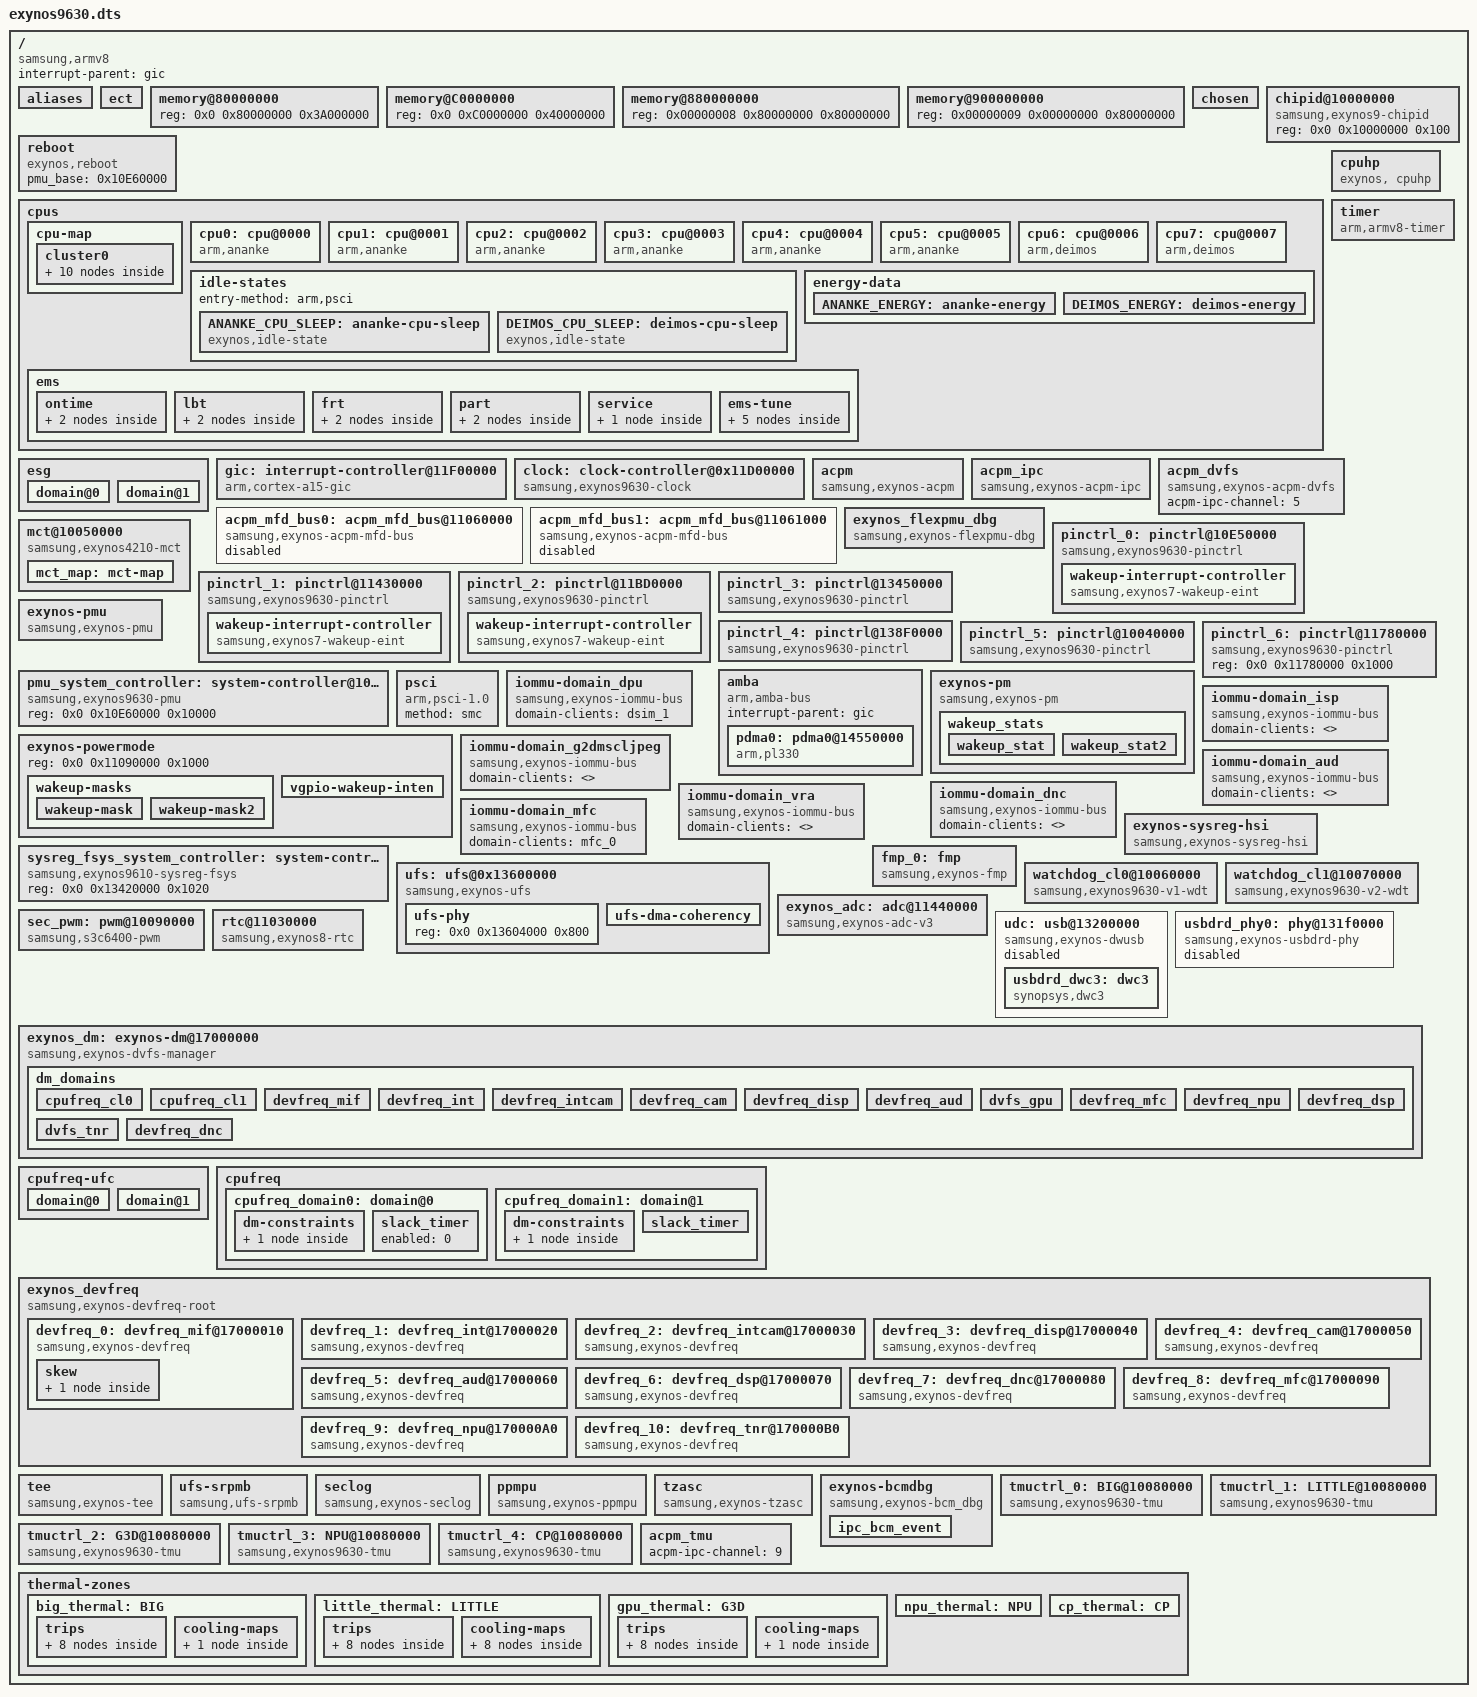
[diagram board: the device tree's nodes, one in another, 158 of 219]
/*
 * SAMSUNG EXYNOS9630 SoC device tree source
 *
 * Copyright (c) 2019 Samsung Electronics Co., Ltd.
 *		http://www.samsung.com
 *
 * SAMSUNG EXYNOS9630 SoC device nodes are listed in this file.
 * EXYNOS9630 based board files can include this file and provide
 * values for board specfic bindings.
 *
 * This program is free software; you can redistribute it and/or modify
 * it under the terms of the GNU General Public License version 2 as
 * published by the Free Software Foundation.
 */

/dts-v1/;
#include <dt-bindings/interrupt-controller/arm-gic.h>
#include <dt-bindings/interrupt-controller/exynos9630.h>
#include <dt-bindings/soc/samsung/exynos-bcm_dbg.h>
#include <dt-bindings/clock/exynos9630.h>
#include "exynos9630-pinctrl.dtsi"
#include "exynos9630-usi.dtsi"
#include "exynos9630-rmem.dtsi"
#include "exynos9630-bts.dtsi"
#include "exynos9630-dpu.dtsi"
#include "exynos9630-sysmmu.dtsi"
#include <dt-bindings/ufs/ufs.h>
#include "exynos9630-mali.dtsi"
#include <dt-bindings/soc/samsung/exynos9630-dm.h>
#include <dt-bindings/soc/samsung/exynos9630-devfreq.h>
#include "exynos9630-pm-domains.dtsi"
#include "exynos9630-debug.dtsi"
#include <dt-bindings/thermal/thermal.h>
#include "exynos9630-mfc.dtsi"

/ {
	compatible = "samsung,armv8", "samsung,exynos9630";
	interrupt-parent = <&gic>;
	#address-cells = <2>;
	#size-cells = <1>;

	aliases {
		pinctrl0 = &pinctrl_0;
		pinctrl1 = &pinctrl_1;
		pinctrl2 = &pinctrl_2;
		pinctrl3 = &pinctrl_3;
		pinctrl4 = &pinctrl_4;
		pinctrl5 = &pinctrl_5;
		pinctrl6 = &pinctrl_6;
		uart0 = &serial_0;
		fmp0 = &fmp_0;
		mfc0 = &mfc_0;
	};

	ect {
		parameter_address = <0x90000000>;
		parameter_size = <0x4B000>;
	};

	memory@80000000 {
		device_type = "memory";
		reg = <0x0 0x80000000 0x3A000000>;
	};

	memory@C0000000 {
		device_type = "memory";
		reg = <0x0 0xC0000000 0x40000000>;
	};

	memory@880000000 {
		device_type = "memory";
		reg = <0x00000008 0x80000000 0x80000000>;
	};

	memory@900000000 {
		device_type = "memory";
		reg = <0x00000009 0x00000000 0x80000000>;
	};

	chosen: chosen {
		bootargs = "console=ram skip_initramfs rootwait ro init=/init root=/dev/sda12 clk_ignore_unused androidboot.hardware=exynos9630 androidboot.selinux=enforce androidboot.debug_level=0x4948 firmware_class.path=/vendor/firmware sec_debug.cp=0";
		linux,initrd-start = <0x84000000>;
		linux,initrd-end = <0x841FFFFF>;
	};

	chipid@10000000 {
		compatible = "samsung,exynos9-chipid";
		reg = <0x0 0x10000000 0x100>;
	};

	reboot {
		compatible = "exynos,reboot";
		pmu_base = <0x10E60000>;
	};

	cpus {
		#address-cells = <2>;
		#size-cells = <0>;

		cpu-map {
			cluster0 {
				coregroup0 {
					core0 {
						cpu = <&cpu0>;
					};
					core1 {
						cpu = <&cpu1>;
					};
					core2 {
						cpu = <&cpu2>;
					};
					core3 {
						cpu = <&cpu3>;
					};
					core4 {
						cpu = <&cpu4>;
					};
					core5 {
						cpu = <&cpu5>;
					};
				};
				coregroup1 {
					core0 {
						cpu = <&cpu6>;
					};
					core1 {
						cpu = <&cpu7>;
					};
				};
			};
		};

		cpu0: cpu@0000 {
			device_type = "cpu";
			compatible = "arm,ananke", "arm,armv8";
			reg = <0x0 0x0>;
			enable-method = "psci";
			sched-energy-data = <&ANANKE_ENERGY>;
			cpu-idle-states = <&ANANKE_CPU_SLEEP>;
		};
		cpu1: cpu@0001 {
			device_type = "cpu";
			compatible = "arm,ananke", "arm,armv8";
			reg = <0x0 0x0001>;
			enable-method = "psci";
			sched-energy-data = <&ANANKE_ENERGY>;
			cpu-idle-states = <&ANANKE_CPU_SLEEP>;
		};
		cpu2: cpu@0002 {
			device_type = "cpu";
			compatible = "arm,ananke", "arm,armv8";
			reg = <0x0 0x0002>;
			enable-method = "psci";
			sched-energy-data = <&ANANKE_ENERGY>;
			cpu-idle-states = <&ANANKE_CPU_SLEEP>;
		};
		cpu3: cpu@0003 {
			device_type = "cpu";
			compatible = "arm,ananke", "arm,armv8";
			reg = <0x0 0x0003>;
			enable-method = "psci";
			sched-energy-data = <&ANANKE_ENERGY>;
			cpu-idle-states = <&ANANKE_CPU_SLEEP>;
		};
		cpu4: cpu@0004 {
			device_type = "cpu";
			compatible = "arm,ananke", "arm,armv8";
			reg = <0x0 0x0004>;
			enable-method = "psci";
			sched-energy-data = <&ANANKE_ENERGY>;
			cpu-idle-states = <&ANANKE_CPU_SLEEP>;
		};
		cpu5: cpu@0005 {
			device_type = "cpu";
			compatible = "arm,ananke", "arm,armv8";
			reg = <0x0 0x0005>;
			enable-method = "psci";
			sched-energy-data = <&ANANKE_ENERGY>;
			cpu-idle-states = <&ANANKE_CPU_SLEEP>;
		};
		cpu6: cpu@0006 {
			device_type = "cpu";
			compatible = "arm,deimos", "arm,armv8";
			reg = <0x0 0x0006>;
			enable-method = "psci";
			sched-energy-data = <&DEIMOS_ENERGY>;
			cpu-idle-states = <&DEIMOS_CPU_SLEEP>;
		};
		cpu7: cpu@0007 {
			device_type = "cpu";
			compatible = "arm,deimos", "arm,armv8";
			reg = <0x0 0x0007>;
			enable-method = "psci";
			sched-energy-data = <&DEIMOS_ENERGY>;
			cpu-idle-states = <&DEIMOS_CPU_SLEEP>;
		};
		
		idle-states {
			entry-method = "arm,psci";

			ANANKE_CPU_SLEEP: ananke-cpu-sleep {
				idle-state-name = "c2";
				compatible = "exynos,idle-state";
				arm,psci-suspend-param = <0x0010000>;
				entry-latency-us = <70>;
				exit-latency-us = <160>;
				min-residency-us = <2000>;
				status = "okay";
			};

			DEIMOS_CPU_SLEEP: deimos-cpu-sleep {
				idle-state-name = "c2";
				compatible = "exynos,idle-state";
				arm,psci-suspend-param = <0x0010000>;
				entry-latency-us = <150>;
				exit-latency-us = <190>;
				min-residency-us = <2500>;
				status = "okay";
			};
		};

		energy-data {
			ANANKE_ENERGY: ananke-energy {
				capacity-mips = <272>;
				power-coefficient = <160>;
				capacity-mips-s = <215>;
				power-coefficient-s = <130>;
				static-power-coefficient = <45>;

				capacity-weight = <1>;
				energy-weight = <1>;
				capacity-weight-perf = <2>;
				energy-weight-perf = <1>;
			};
			DEIMOS_ENERGY: deimos-energy {
				capacity-mips = <785>;
				power-coefficient = <760>;
				capacity-mips-s = <365>;
				power-coefficient-s = <506>;
				static-power-coefficient = <289>;

				capacity-weight = <1>;
				energy-weight = <3>;
				capacity-weight-perf = <3>;
				energy-weight-perf = <1>;
			};
		};

		ems {
			/* Ontime Migration */
			ontime {
				/* little cores */
				coregroup0 {
					lower-boundary = <0>;
					upper-boundary = <106>;
					lower-boundary-s = <0>;
					upper-boundary-s = <60>;
				};
				/* big cores */
				coregroup1 {
					lower-boundary = <204>;
					upper-boundary = <0xffffffff>;
					lower-boundary-s = <309>;
					upper-boundary-s = <0xffffffff>;
				};
			};

			/* Load Balance Trigger */
			#define DEFAULT_RATIO	80
			lbt {
				overutil-level0 {
					cpus =	"0-5",
						"6-7";
					ratio =	<25>,
						<30>;
				};
				overutil-level1 {
					cpus = "0-7";
					ratio = <DEFAULT_RATIO>;
				};
			};

			/* FRT Migration */
			frt {
				/* little cores */
				coregroup0 {
					coverage-ratio = <30>;
					active-ratio = <25>;
				};
				/* big cores */
				coregroup1 {
					coverage-ratio = <30>;
					active-ratio = <5>;
				};
			};

			part {
				/* little cores */
				coregroup0 {
					active-ratio-limit = <43>;
					active-ratio-boost = <42>;
				};
				/* big cores */
				coregroup1 {
					active-ratio-limit = <30>;
					active-ratio-boost = <0>;
				};
			};

			service {
				prefer-perf0 {
					boost = <1>;
					prefer-cpus =	"6-7",
						"0-5";
					light-task-threshold = <10>;
					light-task-threshold-s = <6>;
					light-prefer-cpus = "0-5";
				};
			};

			ems-tune {
				root {
					boost_ratio = <0 0 0>;
				};
				foreground {
					boost_ratio = <0 0 0>;
				};
				background {
					boost_ratio = <0 0 0>;
				};
				top-app {
					boost_ratio = <5 5 5>;
				};
				rt {
					boost_ratio = <0 0 0>;
				};
			};
		};

	};

	esg {
		domain@0 {
			device_type = "esgov-pol0";
			shared-cpus = "0-5";
			pm_qos-min-class = <3>;
			pm_qos-max-class = <4>;
			step = <4>;
		};
		domain@1 {
			device_type = "esgov-pol6";
			shared-cpus = "6-7";
			pm_qos-min-class = <5>;
			pm_qos-max-class = <6>;
			step = <8>;
		};
	};

	cpuhp {
		compatible = "exynos, cpuhp";
	};


	gic:interrupt-controller@11F00000 {
		compatible = "arm,cortex-a15-gic", "arm,cortex-a9-gic";
		#interrupt-cells = <3>;
		#address-cells = <0>;
		interrupt-controller;
		reg =	<0x0 0x11F01000 0x1000>,
			<0x0 0x11F02000 0x1000>,
			<0x0 0x11F04000 0x2000>,
			<0x0 0x11F06000 0x2000>;
		interrupts = <GIC_PPI 9 (GIC_CPU_MASK_SIMPLE(4) | IRQ_TYPE_LEVEL_HIGH)>;
	};

	timer {
		compatible = "arm,armv8-timer";
		interrupts = <GIC_PPI 13
				(GIC_CPU_MASK_SIMPLE(8) | IRQ_TYPE_LEVEL_LOW)>,
			     <GIC_PPI 14
				(GIC_CPU_MASK_SIMPLE(8) | IRQ_TYPE_LEVEL_LOW)>,
			     <GIC_PPI 11
				(GIC_CPU_MASK_SIMPLE(8) | IRQ_TYPE_LEVEL_LOW)>,
			     <GIC_PPI 10
				(GIC_CPU_MASK_SIMPLE(8) | IRQ_TYPE_LEVEL_LOW)>;
	        clock-frequency = <26000000>;
		use-clocksource-only;
		use-physical-timer;
	};

	clock: clock-controller@0x11D00000 {
		compatible = "samsung,exynos9630-clock";
		reg = <0x0 0x11D00000 0x8000>;
		#clock-cells = <1>;
		acpm-ipc-channel = <0>;
	};

	acpm {
		compatible = "samsung,exynos-acpm";
		#address-cells = <2>;
		#size-cells = <1>;
		acpm-ipc-channel = <4>;
		fvmap_offset = <0xCC00>;
		reg = <0x0 0x10E30000 0x1000>;		/* TIMER_APM */
		reg-names = "timer_apm";
		peritimer-cnt = <0xFFFF>;
	};

	acpm_ipc {
		compatible = "samsung,exynos-acpm-ipc";
		#address-cells = <2>;
		#size-cells = <1>;
		interrupts = <GIC_SPI INTREQ__MAILBOX_APM2AP IRQ_TYPE_LEVEL_HIGH>;	/* AP2APM MAILBOX SPI NUM*/
		reg = <0x0 0x10F00000 0x1000>,		/* AP2APM MAILBOX */
			<0x0 0x2039000 0x30000>;	/* APM SRAM */
		initdata-base = <0x7000>;
		num-timestamps = <32>;
		debug-log-level = <0>;
		logging-period = <500>;
		dump-base = <0x203C000>;
		dump-size = <0x2D000>;			/* 180KB */
	};

	acpm_dvfs {
		compatible = "samsung,exynos-acpm-dvfs";
		acpm-ipc-channel = <5>;
	};

	acpm_mfd_bus0: acpm_mfd_bus@11060000 {
		compatible = "samsung,exynos-acpm-mfd-bus";
		status = "disabled";
	};

	acpm_mfd_bus1: acpm_mfd_bus@11061000 {
		compatible = "samsung,exynos-acpm-mfd-bus";
		status = "disabled";
	};

	exynos_flexpmu_dbg {
		compatible = "samsung,exynos-flexpmu-dbg";
		#address-cells = <2>;
		#size-cells = <1>;
		data-base = <0x204f800>;
		data-size = <0x400>;
	};

	mct@10050000 {
		compatible = "samsung,exynos4210-mct";
		reg = <0x0 0x10050000 0x800>;
		interrupt-controller;
		#interrupt-cells = <1>;
		interrupt-parent = <&mct_map>;
		interrupts =	<0>, <1>, <2>, <3>,
				<4>, <5>, <6>, <7>,
				<8>, <9>, <10>, <11>;
		clocks = <&clock OSCCLK>, <&clock GATE_MCT_QCH>;
		clock-names = "fin_pll", "mct";
		use-clockevent-only;

		mct_map: mct-map {
			#interrupt-cells = <1>;
			#address-cells = <0>;
			#size-cells = <0>;
			interrupt-map = <0 &gic 0 INTREQ__MCT_G0 IRQ_TYPE_LEVEL_HIGH>,
					<1 &gic 0 INTREQ__MCT_G1 IRQ_TYPE_LEVEL_HIGH>,
					<2 &gic 0 INTREQ__MCT_G2 IRQ_TYPE_LEVEL_HIGH>,
					<3 &gic 0 INTREQ__MCT_G3 IRQ_TYPE_LEVEL_HIGH>,
					<4 &gic 0 INTREQ__MCT_L0 IRQ_TYPE_LEVEL_HIGH>,
					<5 &gic 0 INTREQ__MCT_L1 IRQ_TYPE_LEVEL_HIGH>,
					<6 &gic 0 INTREQ__MCT_L2 IRQ_TYPE_LEVEL_HIGH>,
					<7 &gic 0 INTREQ__MCT_L3 IRQ_TYPE_LEVEL_HIGH>,
					<8 &gic 0 INTREQ__MCT_L4 IRQ_TYPE_LEVEL_HIGH>,
					<9 &gic 0 INTREQ__MCT_L5 IRQ_TYPE_LEVEL_HIGH>,
					<10 &gic 0 INTREQ__MCT_L6 IRQ_TYPE_LEVEL_HIGH>,
					<11 &gic 0 INTREQ__MCT_L7 IRQ_TYPE_LEVEL_HIGH>;
		};
	};

	/* ALIVE */
	pinctrl_0: pinctrl@10E50000 {
		compatible = "samsung,exynos9630-pinctrl";
		reg = <0x0 0x10E50000 0x1000>;
		interrupts = <GIC_SPI INTREQ__ALIVE_EINT0 0>,
			     <GIC_SPI INTREQ__ALIVE_EINT1 0>,
			     <GIC_SPI INTREQ__ALIVE_EINT2 0>,
			     <GIC_SPI INTREQ__ALIVE_EINT3 0>,
			     <GIC_SPI INTREQ__ALIVE_EINT4 0>,
			     <GIC_SPI INTREQ__ALIVE_EINT5 0>,
			     <GIC_SPI INTREQ__ALIVE_EINT6 0>,
			     <GIC_SPI INTREQ__ALIVE_EINT7 0>,
			     <GIC_SPI INTREQ__ALIVE_EINT8 0>,
			     <GIC_SPI INTREQ__ALIVE_EINT9 0>,
			     <GIC_SPI INTREQ__ALIVE_EINT10 0>,
			     <GIC_SPI INTREQ__ALIVE_EINT11 0>;

		wakeup-interrupt-controller {
			compatible = "samsung,exynos7-wakeup-eint";
		};
	};

	/* CMGP */
	pinctrl_1: pinctrl@11430000 {
		compatible = "samsung,exynos9630-pinctrl";
		reg = <0x0 0x11430000 0x1000>;
		interrupts = <GIC_SPI INTREQ__EXT_INTM00 IRQ_TYPE_LEVEL_HIGH>,
			     <GIC_SPI INTREQ__EXT_INTM01 IRQ_TYPE_LEVEL_HIGH>,
			     <GIC_SPI INTREQ__EXT_INTM02 IRQ_TYPE_LEVEL_HIGH>,
			     <GIC_SPI INTREQ__EXT_INTM03 IRQ_TYPE_LEVEL_HIGH>,
			     <GIC_SPI INTREQ__EXT_INTM04 IRQ_TYPE_LEVEL_HIGH>,
			     <GIC_SPI INTREQ__EXT_INTM05 IRQ_TYPE_LEVEL_HIGH>,
			     <GIC_SPI INTREQ__EXT_INTM06 IRQ_TYPE_LEVEL_HIGH>,
			     <GIC_SPI INTREQ__EXT_INTM07 IRQ_TYPE_LEVEL_HIGH>,
			     <GIC_SPI INTREQ__EXT_INTM08 IRQ_TYPE_LEVEL_HIGH>,
			     <GIC_SPI INTREQ__EXT_INTM09 IRQ_TYPE_LEVEL_HIGH>,
			     <GIC_SPI INTREQ__EXT_INTM10 IRQ_TYPE_LEVEL_HIGH>,
			     <GIC_SPI INTREQ__EXT_INTM11 IRQ_TYPE_LEVEL_HIGH>,
			     <GIC_SPI INTREQ__EXT_INTM12 IRQ_TYPE_LEVEL_HIGH>,
			     <GIC_SPI INTREQ__EXT_INTM13 IRQ_TYPE_LEVEL_HIGH>,
			     <GIC_SPI INTREQ__EXT_INTM14 IRQ_TYPE_LEVEL_HIGH>,
			     <GIC_SPI INTREQ__EXT_INTM15 IRQ_TYPE_LEVEL_HIGH>;

		wakeup-interrupt-controller {
			compatible = "samsung,exynos7-wakeup-eint";
		};
	};

	/* CHUB */
	pinctrl_2: pinctrl@11BD0000 {
		compatible = "samsung,exynos9630-pinctrl";
		reg = <0x0 0x11BD0000 0x1000>;
		interrupts = <GIC_SPI INTREQ__EXT_INTH0_0 IRQ_TYPE_LEVEL_HIGH>,
			     <GIC_SPI INTREQ__EXT_INTH0_1 IRQ_TYPE_LEVEL_HIGH>,
			     <GIC_SPI INTREQ__EXT_INTH0_2 IRQ_TYPE_LEVEL_HIGH>,
			     <GIC_SPI INTREQ__EXT_INTH0_3 IRQ_TYPE_LEVEL_HIGH>,
			     <GIC_SPI INTREQ__EXT_INTH0_4 IRQ_TYPE_LEVEL_HIGH>,
			     <GIC_SPI INTREQ__EXT_INTH0_5 IRQ_TYPE_LEVEL_HIGH>,
			     <GIC_SPI INTREQ__EXT_INTH0_6 IRQ_TYPE_LEVEL_HIGH>,
			     <GIC_SPI INTREQ__EXT_INTH0_7 IRQ_TYPE_LEVEL_HIGH>,
			     <GIC_SPI INTREQ__EXT_INTH1_0 IRQ_TYPE_LEVEL_HIGH>,
			     <GIC_SPI INTREQ__EXT_INTH1_1 IRQ_TYPE_LEVEL_HIGH>,
			     <GIC_SPI INTREQ__EXT_INTH1_2 IRQ_TYPE_LEVEL_HIGH>,
			     <GIC_SPI INTREQ__EXT_INTH1_3 IRQ_TYPE_LEVEL_HIGH>,
			     <GIC_SPI INTREQ__EXT_INTH2_0 IRQ_TYPE_LEVEL_HIGH>,
			     <GIC_SPI INTREQ__EXT_INTH2_1 IRQ_TYPE_LEVEL_HIGH>,
			     <GIC_SPI INTREQ__EXT_INTH2_2 IRQ_TYPE_LEVEL_HIGH>,
			     <GIC_SPI INTREQ__EXT_INTH2_3 IRQ_TYPE_LEVEL_HIGH>,
			     <GIC_SPI INTREQ__EXT_INTH2_4 IRQ_TYPE_LEVEL_HIGH>,
			     <GIC_SPI INTREQ__EXT_INTH2_5 IRQ_TYPE_LEVEL_HIGH>;

		wakeup-interrupt-controller {
			compatible = "samsung,exynos7-wakeup-eint";
		};
	};

	/* HSI */
	pinctrl_3: pinctrl@13450000 {
		compatible = "samsung,exynos9630-pinctrl";
		reg = <0x0 0x13450000 0x1000>;
		interrupts = <GIC_SPI INTREQ__GPIO_HSI 0>;
	};

	/* MMCCARD */
	pinctrl_4: pinctrl@138F0000{
		compatible = "samsung,exynos9630-pinctrl";
		reg = <0x0 0x138F0000 0x1000>;
		interrupts = <GIC_SPI INTREQ__GPIO_MMCCARD 0>;
	};

	/* PERI */
	pinctrl_5: pinctrl@10040000 {
		compatible = "samsung,exynos9630-pinctrl";
		reg = <0x0 0x10040000 0x1000>;
		interrupts = <GIC_SPI INTREQ__GPIO_PERI 0>;
	};

	/* VTS */
	pinctrl_6: pinctrl@11780000 {
		compatible = "samsung,exynos9630-pinctrl";
		reg = <0x0 0x11780000 0x1000>;
	};

	exynos-pmu {
		compatible = "samsung,exynos-pmu";
		samsung,syscon-phandle = <&pmu_system_controller>;
		reg = <0x0 0x10E60000 0x10000>;
		reg-names = "pmu_alive";
	};

	pmu_system_controller: system-controller@10E60000 {
		compatible = "samsung,exynos9630-pmu", "syscon";
		reg = <0x0 0x10E60000 0x10000>;
	};

	/* DMA */
	amba {
		#address-cells = <2>;
		#size-cells = <1>;
		compatible = "arm,amba-bus";
		interrupt-parent = <&gic>;
		ranges;

		pdma0: pdma0@14550000 {
			compatible = "arm,pl330", "arm,primecell";
			reg = <0x0 0x14550000 0x1000>;
			interrupts = <0 37 0>;
			clocks = <&clock GATE_PDMA_BUSC_QCH>;
			clock-names = "apb_pclk";
			#dma-cells = <1>;
			#dma-channels = <8>;
			#dma-requests = <32>;
			#dma-multi-irq = <1>;
			dma-arwrapper = <0x14554400>,
					<0x14554420>,
					<0x14554440>,
					<0x14554460>,
					<0x14554480>,
					<0x145544A0>,
					<0x145544C0>,
					<0x145544E0>;
			dma-awwrapper = <0x14554404>,
					<0x14554424>,
					<0x14554444>,
					<0x14554464>,
					<0x14554484>,
					<0x145544A4>,
					<0x145544C4>,
					<0x145544E4>;
			dma-instwrapper = <0x14554500>;
			dma-mask-bit = <36>;
			coherent-mask-bit = <36>;
		};
	};

	psci {
		compatible = "arm,psci-1.0";
		method = "smc";
	};

	exynos-pm {
		compatible = "samsung,exynos-pm";
		reg = <0x0 0x10E50000 0x1000>,
		    <0x0 0x11F01200 0x100>;
		reg-names = "gpio_alive_base",
			"gicd_ispendrn_base";
		num-eint = <12>;
		num-gic = <16>;
		suspend_mode_idx = <8>;         /* SYS_SLEEP */
		suspend_psci_idx = <1024>;      /* PSCI_SYSTEM_SLEEP */

		usbl2_suspend_available = <0>;  /* SYS_SLEEP_USBL2 */
		usbl2_suspend_mode_idx = <12>;  /* PSCI_SYSTEM_SLEEP */

		/* WAKEUP_STAT,      WAKEUP2_STAT*/
		wakeup_stat = <0x3950>,         <0x3954>;

		wake_lock = <0>;		/* 1: held wake_lock */

		wakeup_stats {
			wakeup_stat {
				ws-name =
					"RTC_ALARM",		/* [ 0] */
					"RTC_TICK",		/* [ 1] */
					"TRTC_ALARM",		/* [ 2] */
					"TRTC_TICK",		/* [ 3] */
					"SPARE",		/* [ 4] */
					"CMGP2PMU_AP_EINT0",	/* [ 5] */
					"CMGP2PMU_AP_EINT1",	/* [ 6] */
					"MAILBOX_APM2AP",	/* [ 7] */
					"MAILBOX_CP2AP",	/* [ 8] */
					"MAILBOX_VTS2AP",	/* [ 9] */
					"S_MAILBOX_CP2AP",	/* [10] */
					"VTS_WDT",		/* [11] */
					"EINT",			/* [12] */
					"MAILBOX_GNSS2AP",	/* [13] */
					"MAILBOX_WLBT2AP",	/* [14] */
					"MAILBOX_CHUB2AP",	/* [15] */
					"RESETREQ_CP",		/* [16] */
					"RESETREQ_GNSS",	/* [17] */
					"RESETREQ_WLBT",	/* [18] */
					"USB_REWA",		/* [19] */
					"USBDP",		/* [20] */
					"MMC_CARD",		/* [21] */
					"TIMER",		/* [22] */
					"CLUSTER0_CPU0_nIRQ",	/* [23] */
					"CLUSTER0_CPU1_nIRQ",	/* [24] */
					"CLUSTER0_CPU2_nIRQ",	/* [25] */
					"CLUSTER0_CPU3_nIRQ",	/* [26] */
					"CLUSTER0_CPU4_nIRQ",	/* [27] */
					"CLUSTER0_CPU5_nIRQ",	/* [28] */
					"CLUSTER1_CPU0_nIRQ",	/* [29] */
					"CLUSTER1_CPU1_nIRQ",	/* [30] */
					"CHUB_WDT";		/* [31] */
			};
			wakeup_stat2 {
				ws-name =
					"CP_ACTIVE",		/* [ 0] */
					"GNSS_ACTIVE",		/* [ 1] */
					"WLBT_ACTIVE",		/* [ 2] */
					"USB20_VMINUS",		/* [ 3] */
					"USB20_VPLUS",		/* [ 4] */
					"RESERVED",		/* [ 5] */
					"RESERVED",		/* [ 6] */
					"RESERVED",		/* [ 7] */
					"MMC_EMBD",		/* [ 8] */
					"GNSS2AP_WAKUP_INT_REQ",/* [ 9] */
					"CHUB2PMU_AP_EINT0",	/* [10] */
					"CHUB2PMU_AP_EINT1",	/* [11] */
					"VGPIO2PMU_EINT0",	/* [12] */
					"VGPIO2PMU_EINT1";	/* [13] */
			};
		};
	};

	exynos-powermode {
		reg = <0x0 0x11090000 0x1000>;
		reg-names = "sysreg_vgpio2pmu";

		wakeup-masks {
			/*
			 * wakeup_mask configuration
			 *	        SICD		SICD_CPD	AFTR		STOP
			 *              LPD		LPA		ALPA		DSTOP
			 *              SLEEP		SLEEP_VTS_ON	SLEEP_AUD_ON	FAPO
			 *		USB_L2		HSI2ON
			 */
			wakeup-mask {
				mask = <0xffffffff>,	<0x0>,		<0x0>,		<0x0>,
				       <0x0>,		<0x0>,		<0x0>,		<0x0>,
				       <0x8007ff6f>,	<0x8007ff6f>,	<0x8007ff6f>,	<0x0>,
				       <0x8007ff6f>,	<0x8007ff6f>;
				mask-offset = <0x3944>;
				stat-offset = <0x3950>;
			};
			wakeup-mask2 {
				mask = <0x3e1e>,	<0x0>,		<0x0>,		<0x0>,
				       <0x0>,		<0x0>,		<0x0>,		<0x0>,
				       <0x3e1e>,	<0x3e1e>,	<0x3e1e>,	<0x0>,
				       <0x3e1e>,	<0x3e1e>;
				mask-offset = <0x3964>;
				stat-offset = <0x3954>;
			};
		};

		vgpio-wakeup-inten {
			mask = <0x0>,		<0x0>,		<0x0>,		<0x0>,
			       <0x0>,		<0x0>,		<0x0>,		<0x0>,
			       <0x19>,		<0x19>,		<0x19>,		<0x0>,
			       <0x19>,		<0x19>;
			inten-offset = <0x0288>;
		};
	};

	iommu-domain_dpu {
		compatible = "samsung,exynos-iommu-bus";
		#dma-address-cells = <2>;
		#dma-size-cells = <1>;
		ranges;

                domain-clients = <&dsim_1>;
	};

	iommu-domain_isp {
		compatible = "samsung,exynos-iommu-bus";
		#dma-address-cells = <2>;
		#dma-size-cells = <1>;
		ranges;

                domain-clients = <>;
	};

	iommu-domain_g2dmscljpeg {
		compatible = "samsung,exynos-iommu-bus";
		#dma-address-cells = <2>;
		#dma-size-cells = <1>;
		ranges;

                domain-clients = <>;
	};

	iommu-domain_aud {
		compatible = "samsung,exynos-iommu-bus";
		#dma-address-cells = <2>;
		#dma-size-cells = <1>;
		ranges;

                domain-clients = <>;
	};

	iommu-domain_dnc {
		compatible = "samsung,exynos-iommu-bus";
		#dma-address-cells = <2>;
		#dma-size-cells = <1>;
		ranges;

                domain-clients = <>;
	};

	iommu-domain_vra {
		compatible = "samsung,exynos-iommu-bus";
		#dma-address-cells = <2>;
		#dma-size-cells = <1>;
		ranges;

                domain-clients = <>;
	};

	iommu-domain_mfc {
		compatible = "samsung,exynos-iommu-bus";
		#dma-address-cells = <2>;
		#dma-size-cells = <1>;
		ranges;

                domain-clients = <&mfc_0>;
	};

	exynos-sysreg-hsi {
		compatible = "samsung,exynos-sysreg-hsi";
		samsung,syscon-phandle = <&sysreg_fsys_system_controller>;
	};

	sysreg_fsys_system_controller: system-controller@13420000 {
		compatible = "samsung,exynos9610-sysreg-fsys", "syscon";
		reg = <0x0 0x13420000 0x1020>;
	};

	fmp_0: fmp {
		compatible = "samsung,exynos-fmp";
	};

	ufs: ufs@0x13600000 {
	     /* ----------------------- */
	     /* 1. SYSTEM CONFIGURATION */
	     /* ----------------------- */
	     compatible ="samsung,exynos-ufs";
	     #address-cells = <2>;
	     #size-cells = <1>;
	     ranges;
	     reg =
		     <0x0 0x13600000 0x200>,	/* 0: HCI standard */
		     <0x0 0x13601100 0x220>,	/* 1: Vendor specificed */
		     <0x0 0x13680000 0xa000>,	/* 2: UNIPRO */
		     <0x0 0x13500000 0x2100>;	/* 3: UFS protector */
	     interrupts = <GIC_SPI INTREQ__UFS_EMBD IRQ_TYPE_LEVEL_HIGH>;
	     pinctrl-names = "default";
	     pinctrl-0 = <&ufs_rst_n &ufs_refclk_out>;
	     clocks =
		     /* aclk clock */
		     <&clock GATE_UFS_EMBD_QCH>,
		     /* unipro clocks */
		     <&clock UFS_EMBD>;

	     clock-names =
		     /* aclk clocks */
		     "GATE_UFS_EMBD_QCH_UFS",
		     /* unipro clocks */
		     "UFS_EMBD";

	     /* PM QoS for INT power domain */
//	     ufs-pm-qos-int = <533000>;

	     /* DMA coherent callback, should be coupled with 'ufs-sys' */
	     dma-coherent;

	     /* UFS PHY isolation and TCXO control */
	     samsung,pmu-phandle = <&pmu_system_controller>;

	     /* TCXO exclusive control  */
	     tcxo-ex-ctrl = <0>;

	     /* UFS IO coherency  */
	     samsung,sysreg-fsys-phandle = <&sysreg_fsys_system_controller>;

	     /* ----------------------- */
	     /* 2. UFS COMMON           */
	     /* ----------------------- */
	     freq-table-hz = <0 0>, <0 0>;

//	     vcc-supply = <&ufs_fixed_vcc>;
//	     vcc-fixed-regulator;
//	     ufs-power-gpio = <&gpa0 0 0>; not used xbootldo
	     ufs-reset-n-gpio = <&gpf0 1 0>;

	     /* ----------------------- */
	     /* 3. UFS EXYNOS           */
	     /* ----------------------- */
	     hw-rev = <UFS_VER_0005>;

	     /* power mode change */
	     ufs,pmd-attr-lane = /bits/ 8 <1>;
	     ufs,pmd-attr-gear = /bits/ 8 <3>;

	     /* hiberantion */
	     ufs-rx-min-activate-time-cap = <3>;
	     ufs-rx-hibern8-time-cap = <2>;
	     ufs-tx-hibern8-time-cap = <2>;

	     /* board type for UFS CAL */
	     brd-for-cal = <0>;

	     fmp-id = <0>;
	     smu-id = <0>;

	     /* ----------------------- */
	     /* 4. ADDITIONAL NODES     */
	     /* ----------------------- */
	     ufs-phy {
		     #address-cells = <2>;
		     #size-cells = <1>;
		     ranges;
		     reg = <0x0 0x13604000 0x800>;
	     };

	     /* SYSREG */
	     ufs-dma-coherency {
		     #address-cells = <2>;
		     #size-cells = <1>;

		     offset = <0x400>;
		     mask = <(BIT_22 | BIT_23)>;
		     val = <(BIT_22 | BIT_23)>;
	     };
	     /*
	      * not confirm this address and can't find cport address
	      ufs-cport {
	      reg =
	      <0x0 0x13108000 0x804>;
	      };
	      */
     };

	watchdog_cl0@10060000 {
		compatible = "samsung,exynos9630-v1-wdt";
		reg = <0x0 0x10060000 0x100>;
		interrupts = <GIC_SPI INTREQ__WDT0 IRQ_TYPE_LEVEL_HIGH>;
		clocks = <&clock OSCCLK>, <&clock GATE_WDT0_QCH>;
		clock-names = "rate_watchdog", "gate_watchdog";
		timeout-sec = <30>;
		samsung,syscon-phandle = <&pmu_system_controller>;
		index = <0>; /* if little cluster then index is 0*/
	};

	watchdog_cl1@10070000 {
		compatible = "samsung,exynos9630-v2-wdt";
		reg = <0x0 0x10070000 0x100>;
		interrupts = <GIC_SPI INTREQ__WDT1 IRQ_TYPE_LEVEL_HIGH>;
		clocks = <&clock OSCCLK>, <&clock GATE_WDT1_QCH>;
		clock-names = "rate_watchdog", "gate_watchdog";
		timeout-sec = <30>;
		samsung,syscon-phandle = <&pmu_system_controller>;
		index = <1>; /* if little cluster then index is 0*/
		use_multistage_wdt; /* Use FIQ debug watchdog */
	};

	exynos_adc: adc@11440000 {
		compatible = "samsung,exynos-adc-v3";
		reg = <0x0 0x11440000 0x100>;
		interrupts = <GIC_SPI INTREQ__ADC_CMGP2AP IRQ_TYPE_LEVEL_HIGH>;
		#io-channel-cells = <1>;
		io-channel-ranges;
		clocks = <&clock GATE_ADC_CMGP_QCH_S0>;
		clock-names = "gate_adcif";
	};

	sec_pwm: pwm@10090000 {
		compatible = "samsung,s3c6400-pwm";
		reg = <0x0 0x10090000 0x1000>;
		samsung,pwm-outputs = <0>, <1>, <2>, <3>, <4>;
		#pwm-cells = <3>;
		clocks = <&clock GATE_PWM_QCH>, <&clock OSCCLK>;
		clock-names = "pwm_pclk", "pwm_sclk";
		status = "ok";
	};

	rtc@11030000 {
		compatible = "samsung,exynos8-rtc";
		reg = <0x0 0x11030000 0x100>;
		interrupts = <GIC_SPI INTREQ__RTC_ALARM_INT IRQ_TYPE_LEVEL_HIGH>,
			     <GIC_SPI INTREQ__RTC_TIC_INT_0 IRQ_TYPE_LEVEL_HIGH>;
	};

	udc: usb@13200000 {
		compatible = "samsung,exynos-dwusb";
		clocks = <&clock GATE_USB31DRD_QCH_SLV_LINK>, <&clock USB31DRD>;
		clock-names = "aclk", "sclk";
		reg = <0x0 0x13200000 0x10000>;
		#address-cells = <2>;
		#size-cells = <1>;
		ranges;
		samsung,power-domain = <&pd_usb>;
		status = "disabled";

		usbdrd_dwc3: dwc3 {
			compatible = "synopsys,dwc3";
			reg = <0x0 0x13200000 0x10000>;
			interrupts = <0 INTREQ__USB31DRD_GIC_0 0>;
			tx-fifo-resize = <0>;
			adj-sof-accuracy = <0>;
			is_not_vbus_pad = <1>;
			enable_sprs_transfer = <1>;
			phys = <&usbdrd_phy0 0>, <&usbdrd_phy0 1>;
			phy-names = "usb2-phy", "usb3-phy";
			/* check susphy support */
			xhci_l2_support = <0>;
			/* support usb audio offloading: 1, if not: 0 */
			usb_audio_offloading = <0>;
			//abox = <&abox>; /* Temporary block */
			/* support USB L2 sleep */
			 ldos = <3>;
			ldo_number = <10 11 12>;
			/* INT min lock support */
			usb-pm-qos-int = <400000>;
		};
	};

	usbdrd_phy0: phy@131f0000 {
		compatible = "samsung,exynos-usbdrd-phy";
		reg = <0x0 0x131f0000 0x200>,
			<0x0 0x130A0000 0x2800>,
			<0x0 0x130B0000 0x800>;
		interrupts = <0 INTREQ__USB2_REMOTE_WAKEUP_GIC 0>,
			     <0 INTREQ__USB2_REMOTE_CONNECT_GIC 0>;
		clocks = <&clock OSCCLK>, <&clock GATE_USB31DRD_QCH_SLV_LINK>;
		clock-names = "ext_xtal", "aclk";
		samsung,pmu-syscon = <&pmu_system_controller>;
		pmu_mask = <0x0>;
		pmu_offset = <0x72c>;
		pmu_offset_dp = <0x704>;

		/* USBDP combo phy version  - 0x200 */
		phy_version = <0x301>;
		/* if it doesn't need phy user mux, */
		/*  you should write "none" */
		/*  but refclk shouldn't be omitted */
		phyclk_mux = "none";
		phy_refclk = "ext_xtal";

		/* if Main phy has the other phy, it must be set to 1. jusf for usbphy_info */
		has_other_phy = <0>;
		/* if combo phy is used, it must be set to 1. usbphy_sub_info is enabled */
		has_combo_phy = <1>;
		sub_phy_version = <0x400>;

		/* ip type */
		/* USB3DRD = 0 */
		/*  USB3HOST = 1 */
		/*  USB2DRD = 2 */
		/*  USB2HOST = 3 */
		ip_type = <0x0>;

		/* for PHY CAL */
		/* choice only one item */
		phy_refsel_clockcore = <1>;
		phy_refsel_ext_osc = <0>;
		phy_refsel_xtal = <0>;
		phy_refsel_diff_pad = <0>;
		phy_refsel_diff_internal = <0>;
		phy_refsel_diff_single = <0>;

		/* true : 1 , false : 0 */
		use_io_for_ovc = <0>;
		common_block_disable = <1>;
		is_not_vbus_pad = <1>;
		used_phy_port = <0>;

		status = "disabled";

		#phy-cells = <1>;
		ranges;
       };

	exynos_dm: exynos-dm@17000000 {
		compatible = "samsung,exynos-dvfs-manager";
		reg = <0x0 0x17000000 0x0>;
		acpm-ipc-channel = <1>;
		dm_domains {
			cpufreq_cl0 {
				dm-index = <DM_CPU_CL0>;
				available = "true";
				cal_id = <ACPM_DVFS_CPUCL0>;
				dm_type_name = "dm_cpu_cl0";
			};
			cpufreq_cl1 {
				dm-index = <DM_CPU_CL1>;
				available = "true";
				cal_id = <ACPM_DVFS_CPUCL1>;
				dm_type_name = "dm_cpu_cl1";
			};
			devfreq_mif {
				dm-index = <DM_MIF>;
				available = "true";
				policy_use = "true";
				cal_id = <ACPM_DVFS_MIF>;
				dm_type_name = "dm_mif";
			};
			devfreq_int {
				dm-index = <DM_INT>;
				available = "true";
				policy_use = "true";
				cal_id = <ACPM_DVFS_INT>;
				dm_type_name = "dm_int";
			};
			devfreq_intcam {
				dm-index = <DM_INTCAM>;
				available = "true";
				cal_id = <ACPM_DVFS_INTCAM>;
				dm_type_name = "dm_intcam";
			};
			devfreq_cam {
				dm-index = <DM_CAM>;
				available = "true";
				cal_id = <ACPM_DVFS_CAM>;
				dm_type_name = "dm_cam";
			};
			devfreq_disp {
				dm-index = <DM_DISP>;
				available = "true";
				cal_id = <ACPM_DVFS_DISP>;
				dm_type_name = "dm_disp";
			};
			devfreq_aud {
				dm-index = <DM_AUD>;
				available = "true";
				cal_id = <ACPM_DVFS_AUD>;
				dm_type_name = "dm_aud";
			};
			dvfs_gpu {
				dm-index = <DM_GPU>;
				available = "false";
				cal_id = <ACPM_DVFS_G3D>;
				dm_type_name = "dm_gpu";
			};
			devfreq_mfc {
				dm-index = <DM_MFC>;
				available = "true";
				cal_id = <ACPM_DVFS_MFC>;
				dm_type_name = "dm_mfc";
			};
			devfreq_npu {
				dm-index = <DM_NPU>;
				available = "true";
				cal_id = <ACPM_DVFS_NPU>;
				dm_type_name = "dm_npu";
			};
			devfreq_dsp {
				dm-index = <DM_DSP>;
				available = "true";
				cal_id = <ACPM_DVFS_DSP>;
				dm_type_name = "dm_dsp";
			};
			dvfs_tnr {
				dm-index = <DM_TNR>;
				available = "true";
				cal_id = <ACPM_DVFS_TNR>;
				dm_type_name = "dm_tnr";
			};
			devfreq_dnc {
				dm-index = <DM_DNC>;
				available = "true";
				cal_id = <ACPM_DVFS_DNC>;
				dm_type_name = "dm_dnc";
			};
		};
	};

	cpufreq-ufc {
		/* Ctrl Type */
		#define PM_QOS_MIN_LIMIT		0
		#define PM_QOS_MIN_WO_BOOST_LIMIT	1
		#define PM_QOS_MAX_LIMIT		2
		/* Execution Mode */
		#define	AARCH64_MODE			0
		#define AARCH32_MODE			1

		domain@0 {
			device_type = "cpufreq-userctrl";
			shared-cpus = "0-5";
			user-default-qos = <806000>;
			user-boost = <0>;
		};

		domain@1 {
			device_type = "cpufreq-userctrl";
			shared-cpus = "6-7";
			user-default-qos = <845000>;
			user-boost = <1>;
		};
	};

	cpufreq {
		cpufreq_domain0: domain@0 {
			device_type = "cpufreq-domain";
			sibling-cpus = "0-5";
			cal-id = <ACPM_DVFS_CPUCL0>;
			dm-type = <DM_CPU_CL0>;

			max-freq = <1105000>;
			min-freq = <208000>;

			/* PM QoS Class ID*/
			pm_qos-min-class = <3>;
			pm_qos-max-class = <4>;

			user-default-qos = <806000>;

			#cooling-cells = <2>; /* min followed by max */

			dm-constraints {
				mif-perf {
					const-type = <CONSTRAINT_MIN>;
					dm-type = <DM_MIF>;
					/*  cpu     mif  */
					table = < 1794000  1014000
						1638000  1014000
						1508000  845000
						1378000  845000
						1248000  845000
						1105000  676000
						949000  676000
						806000  676000
						650000  676000
						546000  546000
						650000  546000
						546000  546000
						442000  421000
						351000  421000
						208000       0
						>;
				};
			};

			slack_timer {
				device_type = "slack-timer-domain";

				enabled = <0>;          /* Disabled */
			};
		};

		cpufreq_domain1: domain@1 {
			device_type = "cpufreq-domain";
			sibling-cpus = "6-7";
			cal-id = <ACPM_DVFS_CPUCL1>;
			dm-type = <DM_CPU_CL1>;

			max-freq = <1404000>;
			min-freq = <377000>;

			/* PM QoS Class ID*/
			pm_qos-min-class = <5>;
			pm_qos-max-class = <6>;

			user-default-qos = <845000>;

			#cooling-cells = <2>; /* min followed by max */

			dm-constraints {
				mif-perf {
					const-type = <CONSTRAINT_MIN>;
					dm-type = <DM_MIF>;
					/*  cpu     mif  */
					table = < 2400000  2093000
						2314000  2093000
						2210000  2093000
						2106000  1794000
						2002000  1794000
						1898000  1794000
						1794000  1539000
						1690000  1539000
						1586000  1352000
						1404000  1352000
						1222000  1014000
						1066000  1014000
						962000    845000
						845000    845000
						754000    676000
						650000    546000
						507000       0
						377000       0
						>;
				};
			};

			slack_timer {
				device_type = "slack-timer-domain";

				enabled = <1>;          /* Enabled */
				expired_time = <80>;    /* 80ms */
			};
		};

	};

	exynos_devfreq {
		compatible = "samsung,exynos-devfreq-root";
		#address-cells = <2>;
		#size-cells = <1>;
		ranges;
		devfreq_0: devfreq_mif@17000010 {
			compatible = "samsung,exynos-devfreq";
			reg = <0x0 0x17000010 0x0>;
			devfreq_type = <DEVFREQ_MIF>;
			devfreq_domain_name = "MIF";
			pm_qos_class = <DT_PM_QOS_BUS_THROUGHPUT>; /* PM_QOS_BUS_THROUGHPUT */
			pm_qos_class_max = <DT_PM_QOS_BUS_THROUGHPUT_MAX>; /* PM_QOS_BUS_THROUGHPUT_MAX */
			ess_flag = <ESS_FLAG_MIF>;
			dm-index = <DM_MIF>;

			/* Delay time */
			use_delay_time = "false";

			freq_info = <2093000 421000 421000 421000 2093000 421000>;
			/* initial_freq, default_qos, suspend_freq, min_freq, max_freq reboot_freq */

			/* Booting value */
			boot_info = <40 2093000>;
			/* boot_qos_timeout, boot_freq */

			/* governor data */
			governor = <SIMPLE_INTERACTIVE>;

			bts_update = "false";
			dfs_id = <ACPM_DVFS_MIF>;
			acpm-ipc-channel = <1>;
			use_acpm = "true";
			update_fvp = "true";
			skew {
				skew_0 {
					constraint_dm_type = <DM_INT>;
					constraint_type = <CONSTRAINT_MIN>;
				};
			};
		};

		devfreq_1: devfreq_int@17000020 {
			compatible = "samsung,exynos-devfreq";
			reg = <0x0 0x17000020 0x0>;
			devfreq_type = <DEVFREQ_INT>;
			devfreq_domain_name = "INT";
			pm_qos_class = <DT_PM_QOS_DEVICE_THROUGHPUT>; /* PM_QOS_DEVICE_THROUGHPUT */
			pm_qos_class_max = <DT_PM_QOS_DEVICE_THROUGHPUT_MAX>; /* PM_QOS_DEVICE_THROUGHPUT_MAX */
			ess_flag = <ESS_FLAG_INT>;
			dm-index = <DM_INT>;

			/* Delay time */
			use_delay_time = "false";

			freq_info = <666000 133000 133000 133000 666000 133000>;
			/* <initial_freq, default_qos, suspend_freq, min, max, reboot_freq> */

			/* Booting value */
			boot_info = <40 666000>;
			/* boot_qos_timeout, boot_freq */

			/* governor data */
			governor = <SIMPLE_INTERACTIVE>;

			bts_update = "false";
			dfs_id = <ACPM_DVFS_INT>;
			acpm-ipc-channel = <1>;
			use_acpm = "true";
		};

		devfreq_2: devfreq_intcam@17000030 {
			compatible = "samsung,exynos-devfreq";
			reg = <0x0 0x17000030 0x0>;
			devfreq_type = <DEVFREQ_INTCAM>;
			devfreq_domain_name = "INTCAM";
			pm_qos_class = <DT_PM_QOS_INTCAM_THROUGHPUT>; /* PM_QOS_INTCAM_THROUGHPUT */
			pm_qos_class_max = <DT_PM_QOS_INTCAM_THROUGHPUT_MAX>; /* PM_QOS_INTCAM_THROUGHPUT_MAX */
			ess_flag = <ESS_FLAG_INTCAM>;
			dm-index = <DM_INTCAM>;

			/* Delay time */
			use_delay_time = "false";

			freq_info = <533000 107000 107000 107000 533000 107000>;
			/* <initial_freq, default_qos, suspend_freq, min, max, reboot_freq> */

			/* Booting value */
			boot_info = <40 533000>;
			/* boot_qos_timeout, boot_freq */

			/* governor data */
			governor = <SIMPLE_INTERACTIVE>;

			bts_update = "false";
			dfs_id = <ACPM_DVFS_INTCAM>;
		};

		devfreq_3: devfreq_disp@17000040 {
			compatible = "samsung,exynos-devfreq";
			reg = <0x0 0x17000040 0x0>;
			devfreq_type = <DEVFREQ_DISP>;
			devfreq_domain_name = "DISP";
			pm_qos_class = <DT_PM_QOS_DISPLAY_THROUGHPUT>; /* PM_QOS_DISPLAY_THROUGHPUT */
			pm_qos_class_max = <DT_PM_QOS_DISPLAY_THROUGHPUT_MAX>; /* PM_QOS_DISPLAY_THROUGHPUT_MAX */
			ess_flag = <ESS_FLAG_DISP>;
			dm-index = <DM_DISP>;

			/* Delay time */
			use_delay_time = "false";

			freq_info = <533000 400000 80000 80000 533000 400000>;
			/* <initial_freq, default_qos, suspend_freq, min, max, reboot_freq> */

			/* Booting value */
			boot_info = <40 533000>;
			/* boot_qos_timeout, boot_freq */

			/* governor data */
			governor = <SIMPLE_INTERACTIVE>;

			bts_update = "false";
			dfs_id = <ACPM_DVFS_DISP>;
		};

		devfreq_4: devfreq_cam@17000050 {
			compatible = "samsung,exynos-devfreq";
			reg = <0x0 0x17000050 0x0>;
			devfreq_type = <DEVFREQ_CAM>;
			devfreq_domain_name = "CAM";
			pm_qos_class = <DT_PM_QOS_CAM_THROUGHPUT>; /* PM_QOS_CAM_THROUGHPUT */
			pm_qos_class_max = <DT_PM_QOS_CAM_THROUGHPUT_MAX>; /* PM_QOS_CAM_THROUGHPUT_MAX */
			ess_flag = <ESS_FLAG_CAM>;
			dm-index = <DM_CAM>;

			/* Delay time */
			use_delay_time = "false";

			freq_info = <533000 100000 100000 100000 533000 100000>;
			/* <initial, default_qos, suspend_freq, min, max, reboot_freq> */

			/* Booting value */
			boot_info = <40 533000>;
			/* boot_qos_timeout, boot_freq */

			/* governor data */
			governor = <SIMPLE_INTERACTIVE>;

			bts_update = "false";

			dfs_id = <ACPM_DVFS_CAM>;
		};

		devfreq_5: devfreq_aud@17000060 {
			compatible = "samsung,exynos-devfreq";
			reg = <0x0 0x17000060 0x0>;
			devfreq_type = <DEVFREQ_AUD>;
			devfreq_domain_name = "AUD";
			pm_qos_class = <DT_PM_QOS_AUD_THROUGHPUT>; /* PM_QOS_AUD_THROUGHPUT */
			pm_qos_class_max = <DT_PM_QOS_AUD_THROUGHPUT_MAX>; /* PM_QOS_AUD_THROUGHPUT_MAX */
			ess_flag = <ESS_FLAG_AUD>;
			dm-index = <DM_AUD>;

			/* Delay time */
			use_delay_time = "false";

			freq_info = <1180000 295000 295000 295000 1180000 295000>;
			/* <initial, default_qos, suspend_freq, min, max, reboot_freq> */

			/* Booting value */
			boot_info = <40 1180000>;
			/* boot_qos_timeout, boot_freq */

			/* governor data */
			governor = <SIMPLE_INTERACTIVE>;

			bts_update = "false";
			dfs_id = <ACPM_DVFS_AUD>;

			samsung,power-domain = <&pd_aud>;
			pd_name = "pd-aud";
		};

		devfreq_6: devfreq_dsp@17000070 {
			compatible = "samsung,exynos-devfreq";
			reg = <0x0 0x17000070 0x0>;
			devfreq_type = <DEVFREQ_DSP>;
			devfreq_domain_name = "DSP";
			pm_qos_class = <DT_PM_QOS_DSP_THROUGHPUT>; /* PM_QOS_DSP_THROUGHPUT */
			pm_qos_class_max = <DT_PM_QOS_DSP_THROUGHPUT_MAX>; /* PM_QOS_DSP_THROUGHPUT_MAX */
			ess_flag = <ESS_FLAG_DSP>;
			dm-index = <DM_DSP>;

			/* Delay time */
			use_delay_time = "false";

			freq_info = <800000 133000 133000 133000 800000 133000>;
			/* <initial, default_qos, suspend_freq, min, max, reboot_freq> */

			/* Booting value */
			boot_info = <40 800000>;
			/* boot_qos_timeout, boot_freq */

			/* governor data */
			governor = <SIMPLE_INTERACTIVE>;

			bts_update = "false";
			dfs_id = <ACPM_DVFS_DSP>;
		};

		devfreq_7: devfreq_dnc@17000080 {
			compatible = "samsung,exynos-devfreq";
			reg = <0x0 0x17000080 0x0>;
			devfreq_type = <DEVFREQ_DNC>;
			devfreq_domain_name = "DNC";
			pm_qos_class = <DT_PM_QOS_DNC_THROUGHPUT>; /* PM_QOS_DNC_THROUGHPUT */
			pm_qos_class_max = <DT_PM_QOS_DNC_THROUGHPUT_MAX>; /* PM_QOS_DNC_THROUGHPUT_MAX */
			ess_flag = <ESS_FLAG_DNC>;
			dm-index = <DM_DNC>;

			/* Delay time */
			use_delay_time = "false";

			freq_info = <800000 133000 133000 133000 800000 133000>;
			/* <initial, default_qos, suspend_freq, min, max, reboot_freq> */

			/* Booting value */
			boot_info = <40 800000>;
			/* boot_qos_timeout, boot_freq */

			/* governor data */
			governor = <SIMPLE_INTERACTIVE>;

			bts_update = "false";
			dfs_id = <ACPM_DVFS_DNC>;
		};

		devfreq_8: devfreq_mfc@17000090 {
			compatible = "samsung,exynos-devfreq";
			reg = <0x0 0x17000090 0x0>;
			devfreq_type = <DEVFREQ_MFC>;
			devfreq_domain_name = "MFC";
			pm_qos_class = <DT_PM_QOS_MFC_THROUGHPUT>; /* PM_QOS_MFC_THROUGHPUT */
			pm_qos_class_max = <DT_PM_QOS_MFC_THROUGHPUT_MAX>; /* PM_QOS_MFC_THROUGHPUT_MAX */
			ess_flag = <ESS_FLAG_MFC>;
			dm-index = <DM_MFC>;

			/* Delay time */
			use_delay_time = "false";

			freq_info = <666000 100000 100000 100000 666000 100000>;
			/* <initial, default_qos, suspend_freq, min, max, reboot_freq> */

			/* Booting value */
			boot_info = <40 666000>;
			/* boot_qos_timeout, boot_freq */

			/* governor data */
			governor = <SIMPLE_INTERACTIVE>;

			bts_update = "false";
			dfs_id = <ACPM_DVFS_MFC>;
		};

		devfreq_9: devfreq_npu@170000A0 {
			compatible = "samsung,exynos-devfreq";
			reg = <0x0 0x170000A0 0x0>;
			devfreq_type = <DEVFREQ_NPU>;
			devfreq_domain_name = "NPU";
			pm_qos_class = <DT_PM_QOS_NPU_THROUGHPUT>; /* PM_QOS_NPU_THROUGHPUT */
			pm_qos_class_max = <DT_PM_QOS_NPU_THROUGHPUT_MAX>; /* PM_QOS_NPU_THROUGHPUT_MAX */
			ess_flag = <ESS_FLAG_NPU>;
			dm-index = <DM_NPU>;

			/* Delay time */
			use_delay_time = "false";

			freq_info = <800000 133000 133000 133000 800000 133000>;
			/* <initial, default_qos, suspend_freq, min, max, reboot_freq> */

			/* Booting value */
			boot_info = <40 800000>;
			/* boot_qos_timeout, boot_freq */

			/* governor data */
			governor = <SIMPLE_INTERACTIVE>;

			bts_update = "false";
			dfs_id = <ACPM_DVFS_NPU>;
		};

		devfreq_10: devfreq_tnr@170000B0 {
			compatible = "samsung,exynos-devfreq";
			reg = <0x0 0x170000B0 0x0>;
			devfreq_type = <DEVFREQ_TNR>;
			devfreq_domain_name = "TNR";
			pm_qos_class = <DT_PM_QOS_TNR_THROUGHPUT>; /* PM_QOS_TNR_THROUGHPUT */
			pm_qos_class_max = <DT_PM_QOS_TNR_THROUGHPUT_MAX>; /* PM_QOS_TNR_THROUGHPUT_MAX */
			ess_flag = <ESS_FLAG_TNR>;
			dm-index = <DM_TNR>;

			/* Delay time */
			use_delay_time = "false";

			freq_info = <533000 107000 107000 107000 533000 107000>;
			/* <initial, default_qos, suspend_freq, min, max, reboot_freq> */

			/* Booting value */
			boot_info = <40 533000>;
			/* boot_qos_timeout, boot_freq */

			/* governor data */
			governor = <SIMPLE_INTERACTIVE>;

			bts_update = "false";
			dfs_id = <ACPM_DVFS_TNR>;
		};
	};

	/* tbase */
        tee {
	        compatible = "samsung,exynos-tee";
		interrupts = <GIC_SPI INTREQ__TBASE IRQ_TYPE_LEVEL_HIGH>;
	};

	/* Secure RPMB */
	ufs-srpmb {
		compatible = "samsung,ufs-srpmb";
		interrupts = <GIC_SPI INTREQ__RPMB IRQ_TYPE_LEVEL_HIGH>;
	};

	/* Secure Log */
	seclog {
		compatible = "samsung,exynos-seclog";
		interrupts = <GIC_SPI INTREQ__SECURE_LOG IRQ_TYPE_LEVEL_HIGH>;
	};

	ppmpu {
		compatible = "samsung,exynos-ppmpu";
		channel = <2>;
		irqcnt = <2>;
		interrupts = <GIC_SPI INTREQ__DMC_INTR_MIF0 IRQ_TYPE_LEVEL_HIGH>,
			     <GIC_SPI INTREQ__DMC_INTR_MIF1 IRQ_TYPE_LEVEL_HIGH>;
	};

	tzasc {
		compatible = "samsung,exynos-tzasc";
		channel = <2>;
		interleaving_shift = <1>;
		tzc_ver = <380>;
		irqcnt = <2>;
		interrupts = <GIC_SPI INTREQ__DMC_INTR_MIF0 IRQ_TYPE_LEVEL_HIGH>,
			     <GIC_SPI INTREQ__DMC_INTR_MIF1 IRQ_TYPE_LEVEL_HIGH>;
	};

	exynos-bcmdbg {
		compatible = "samsung,exynos-bcm_dbg";

		pd-name = "pd-trex", "pd-aud", "pd-npu0", "pd-npu1", "pd-dpu",
			  "pd-g2d", "pd-g3d", "pd-csis", "pd-ipp", "pd-mcsc",
			  "pd-mfc", "pd-usb", "pd-tnr", "pd-dnc", "pd-dns",
			  "pd-vra";

		max_define_event = <PRE_DEFINE_EVT_MAX>;
		bcm_cnt_nr = <8>;
		/* define_event_index ev0 ev1 ev2 ev3 ev4 ev5 ev6 ev7 */
		define_events = <NO_PRE_DEFINE_EVT	0x0  0x0  0x0  0x0  0x0  0x0  0x0  0x0>,
				<LATENCY_FMT_EVT	0x4  0x2  0x26 0x24 0x5  0x3  0x27 0x25>,
				<MO_FMT_EVT		0x4  0x0  0x24 0x24 0x5  0x1  0x25 0x25>,
				<BURST_LENGTH_FMT_EVT	0x4  0x2  0x4  0x26 0x5  0x3  0x5  0x27>,
				<REQ_BLOCK_FMT_EVT	0x2  0x10 0x10 0x26 0x3  0x11 0x11 0x27>,
				<DATA_BLOCK_FMT_EVT	0x4  0x12 0x12 0x6  0x5  0x13 0x13 0x14>,
				<REQ_TYPE_FMT_EVT	0x2  0x15 0x18 0x1B 0x3  0x16 0x19 0x1C>;
		default_define_event = <LATENCY_FMT_EVT>;

		/* sm_id_mask sm_id_value */
		define_filter_id = <NO_PRE_DEFINE_EVT	0x0  0x0>,
				<LATENCY_FMT_EVT	0x0  0x0>,
				<MO_FMT_EVT		0x0  0x0>,
				<BURST_LENGTH_FMT_EVT	0x0  0x0>,
				<REQ_BLOCK_FMT_EVT	0x0  0x0>,
				<DATA_BLOCK_FMT_EVT	0x0  0x0>,
				<REQ_TYPE_FMT_EVT	0x0  0x0>;
		/* ev0 ev1 ev2 ev3 ev4 ev5 ev6 ev7 */
		define_filter_id_active = <NO_PRE_DEFINE_EVT	0x0  0x0  0x0  0x0  0x0  0x0  0x0  0x0>,
					<LATENCY_FMT_EVT	0x0  0x0  0x0  0x0  0x0  0x0  0x0  0x0>,
					<MO_FMT_EVT		0x0  0x0  0x0  0x0  0x0  0x0  0x0  0x0>,
					<BURST_LENGTH_FMT_EVT	0x0  0x0  0x0  0x0  0x0  0x0  0x0  0x0>,
					<REQ_BLOCK_FMT_EVT	0x0  0x0  0x0  0x0  0x0  0x0  0x0  0x0>,
					<DATA_BLOCK_FMT_EVT	0x0  0x0  0x0  0x0  0x0  0x0  0x0  0x0>,
					<REQ_TYPE_FMT_EVT	0x0  0x0  0x0  0x0  0x0  0x0  0x0  0x0>;
		/* sm_other_type0 sm_other_mask0 sm_other_value0 */
		define_filter_other_0 = <NO_PRE_DEFINE_EVT	0x0  0x0  0x0>,
					<LATENCY_FMT_EVT	0x0  0x0  0x0>,
					<MO_FMT_EVT		0x0  0x0  0x0>,
					<BURST_LENGTH_FMT_EVT	0x0  0x0  0x0>,
					<REQ_BLOCK_FMT_EVT	0x0  0x0  0x0>,
					<DATA_BLOCK_FMT_EVT	0x0  0x0  0x0>,
					<REQ_TYPE_FMT_EVT	0x0  0x0  0x0>;
		/* sm_other_type1 sm_other_mask1 sm_other_value1 */
		define_filter_other_1 = <NO_PRE_DEFINE_EVT	0x0  0x0  0x0>,
					<LATENCY_FMT_EVT	0x0  0x0  0x0>,
					<MO_FMT_EVT		0x0  0x0  0x0>,
					<BURST_LENGTH_FMT_EVT	0x0  0x0  0x0>,
					<REQ_BLOCK_FMT_EVT	0x0  0x0  0x0>,
					<DATA_BLOCK_FMT_EVT	0x0  0x0  0x0>,
					<REQ_TYPE_FMT_EVT	0x0  0x0  0x0>;
		/* ev0 ev1 ev2 ev3 ev4 ev5 ev6 ev7 */
		define_filter_other_active = <NO_PRE_DEFINE_EVT	0x0  0x0  0x0  0x0  0x0  0x0  0x0  0x0>,
					<LATENCY_FMT_EVT	0x0  0x0  0x0  0x0  0x0  0x0  0x0  0x0>,
					<MO_FMT_EVT		0x0  0x0  0x0  0x0  0x0  0x0  0x0  0x0>,
					<BURST_LENGTH_FMT_EVT	0x0  0x0  0x0  0x0  0x0  0x0  0x0  0x0>,
					<REQ_BLOCK_FMT_EVT	0x0  0x0  0x0  0x0  0x0  0x0  0x0  0x0>,
					<DATA_BLOCK_FMT_EVT	0x0  0x0  0x0  0x0  0x0  0x0  0x0  0x0>,
					<REQ_TYPE_FMT_EVT	0x0  0x0  0x0  0x0  0x0  0x0  0x0  0x0>;

		/* peak_mask peak_id */
		define_sample_id = <NO_PRE_DEFINE_EVT	0x0  0x0>,
				<LATENCY_FMT_EVT	0x0  0x0>,
				<MO_FMT_EVT		0x0  0x0>,
				<BURST_LENGTH_FMT_EVT	0x0  0x0>,
				<REQ_BLOCK_FMT_EVT	0x0  0x0>,
				<DATA_BLOCK_FMT_EVT	0x0  0x0>,
				<REQ_TYPE_FMT_EVT	0x0  0x0>;
		/* ev0 ev1 ev2 ev3 ev4 ev5 ev6 ev7 */
		define_sample_id_enable = <NO_PRE_DEFINE_EVT	0x0  0x0  0x0  0x0  0x0  0x0  0x0  0x0>,
					<LATENCY_FMT_EVT	0x0  0x0  0x1  0x0  0x0  0x0  0x1  0x0>,
					<MO_FMT_EVT		0x0  0x0  0x1  0x0  0x0  0x0  0x1  0x0>,
					<BURST_LENGTH_FMT_EVT	0x0  0x0  0x1  0x1  0x0  0x0  0x1  0x1>,
					<REQ_BLOCK_FMT_EVT	0x0  0x0  0x1  0x1  0x0  0x0  0x1  0x1>,
					<DATA_BLOCK_FMT_EVT	0x0  0x0  0x1  0x0  0x0  0x0  0x1  0x0>,
					<REQ_TYPE_FMT_EVT	0x0  0x0  0x0  0x0  0x0  0x0  0x0  0x0>;

		bcm_ip_nr = <56>;
		bcm_ip_print_nr = <10>;
		initial_run_bcm_ip = <0>, <1>, <2>, <3>, <4>, <5>, <6>, <7>, <8>, <9>, <10>,
				<11>, <12>, <13>, <14>, <15>, <16>, <17>, <18>,	<19>, <20>,
				<21>, <22>, <23>, <24>, <25>, <26>, <27>, <28>, <29>, <30>,
				<31>, <32>, <33>, <34>, <35>, <36>, <37>, <38>, <39>, <40>,
				<41>, <42>, <43>, <44>, <45>, <46>, <47>, <48>, <49>, <50>,
				<51>, <52>, <53>, <54>, <55>;
		initial_bcm_run = <BCM_STOP>;
		/* msec (max 500msec) */
		initial_period = <1>;
		initial_bcm_mode = <BCM_MODE_INTERVAL>;
		available_stop_owner = <PANIC_HANDLE CAMERA_DRIVER MODEM_IF ITMON_HANDLE>;
		buff_size = <0x200000>;
		glb_auto_en = <1>;

		ipc_bcm_event {
			plugin-len = <5>;
			plugin-name = "BCM";
		};
	};

	tmuctrl_0: BIG@10080000 {
		compatible = "samsung,exynos9630-tmu";
		reg = <0x0 0x10080000 0x800>;
		interrupts = <0 INTREQ__TMU 0>;
		tmu_name = "BIG";
		id = <0>;
		sensors = <448>;	/* 0x1C0 */
		sensing_mode = "max";
		hotplug_enable = <1>;
		hotplug_in_threshold = <91>;
		hotplug_out_threshold = <96>;
		#include "exynos9630-tmu-sensor-conf.dtsi"
	};

	tmuctrl_1: LITTLE@10080000 {
		compatible = "samsung,exynos9630-tmu";
		reg = <0x0 0x10080000 0x800>;
		interrupts = <0 INTREQ__TMU 0>;
		tmu_name = "LITTLE";
		id = <1>;
		sensors = <1>;	/* 0x1 */
		sensing_mode = "max";
		#include "exynos9630-tmu-sensor-conf.dtsi"
	};

	tmuctrl_2: G3D@10080000 {
		compatible = "samsung,exynos9630-tmu";
		reg = <0x0 0x10080000 0x800>;
		interrupts = <0 INTREQ__TMU 0>;
		tmu_name = "G3D";
		id = <2>;
		sensors = <48>;	/* 0x30 */
		sensing_mode = "max";
		#include "exynos9630-tmu-sensor-conf.dtsi"
	};

	tmuctrl_3: NPU@10080000 {
		compatible = "samsung,exynos9630-tmu";
		reg = <0x0 0x10080000 0x800>;
		interrupts = <0 INTREQ__TMU 0>;
		tmu_name = "NPU";
		id = <3>;
		sensors = <8>;	/* 0x8 */
		sensing_mode = "max";
		ect_nouse = <1>;
		#include "exynos9630-tmu-sensor-conf.dtsi"
	};

	tmuctrl_4: CP@10080000 {
		compatible = "samsung,exynos9630-tmu";
		reg = <0x0 0x10080000 0x800>;
		interrupts = <0 INTREQ__TMU 0>;
		tmu_name = "CP";
		id = <4>;
		sensors = <6>;	/* 0x6 */
		sensing_mode = "max";
		ect_nouse = <1>;
		#include "exynos9630-tmu-sensor-conf.dtsi"
	};

	acpm_tmu {
		acpm-ipc-channel = <9>;
	};

	thermal-zones {
		big_thermal: BIG {
			zone_name = "BIG_THERMAL";
			polling-delay-passive = <50>;
			polling-delay = <1000>;
			thermal-sensors = <&tmuctrl_0>;
			governor = "power_allocator";
			sustainable-power = <0>;
			k_po = <0>;
			k_pu = <0>;
			k_i = <0>;
			i_max = <0>;
			integral_cutoff = <0>;

			trips {
				big_cold: big-cold {
					temperature = <20000>;
					hysteresis = <5000>; /* millicelsius */
					type = "active";
				};
				big_switch_on: big-switch-on {
					temperature = <60000>; /* millicelsius */
					hysteresis = <2000>; /* millicelsius */
					type = "active";
				};
				big_control_temp: big-control-temp {
					temperature = <83000>; /* millicelsius */
					hysteresis = <5000>; /* millicelsius */
					type = "passive";
				};
				big_alert0: big-alert0 {
					temperature = <95000>; /* millicelsius */
					hysteresis = <5000>; /* millicelsius */
					type = "active";
				};
				big_alert1: big-alert1 {
					temperature = <100000>; /* millicelsius */
					hysteresis = <5000>; /* millicelsius */
					type = "active";
				};
				big_alert2: big-alert2 {
					temperature = <105000>; /* millicelsius */
					hysteresis = <5000>; /* millicelsius */
					type = "active";
				};
				big_alert3: big-alert3 {
					temperature = <110000>; /* millicelsius */
					hysteresis = <5000>; /* millicelsius */
					type = "active";
				};
				big_hot: big-hot {
					temperature = <115000>; /* millicelsius */
					hysteresis = <5000>; /* millicelsius */
					type = "hot";
				};
			};

			cooling-maps {
				map0 {
					trip = <&big_control_temp>;
					cooling-device = <&cpufreq_domain1 THERMAL_NO_LIMIT THERMAL_NO_LIMIT>;
				};
			};
		};

		little_thermal: LITTLE {
			zone_name = "LITTLE_THERMAL";
			polling-delay-passive = <0>;
			polling-delay = <0>;
			thermal-sensors = <&tmuctrl_1>;

			trips {
				little_alert0: little-alert0 {
					temperature = <20000>;
					hysteresis = <5000>; /* millicelsius */
					type = "active";
				};
				little_alert1: little-alert1 {
					temperature = <76000>; /* millicelsius */
					hysteresis = <2000>; /* millicelsius */
					type = "active";
				};
				little_alert2: little-alert2 {
					temperature = <81000>; /* millicelsius */
					hysteresis = <5000>; /* millicelsius */
					type = "active";
				};
				little_alert3: little-alert3 {
					temperature = <86000>; /* millicelsius */
					hysteresis = <5000>; /* millicelsius */
					type = "active";
				};
				little_alert4: little-alert4 {
					temperature = <91000>; /* millicelsius */
					hysteresis = <5000>; /* millicelsius */
					type = "active";
				};
				little_alert5: little-alert5 {
					temperature = <96000>; /* millicelsius */
					hysteresis = <5000>; /* millicelsius */
					type = "active";
				};
				little_alert6: little-alert6 {
					temperature = <101000>; /* millicelsius */
					hysteresis = <5000>; /* millicelsius */
					type = "active";
				};
				little_hot: little-hot {
					temperature = <115000>; /* millicelsius */
					hysteresis = <5000>; /* millicelsius */
					type = "hot";
				};
			};

			cooling-maps {
				map0 {
					trip = <&little_alert0>;
					cooling-device = <&cpufreq_domain0 0 0>;
				};
				map1 {
					trip = <&little_alert1>;
					cooling-device = <&cpufreq_domain0 0 0>;
				};
				map2 {
					trip = <&little_alert2>;
					cooling-device = <&cpufreq_domain0 0 0>;
				};
				map3 {
					trip = <&little_alert3>;
					cooling-device = <&cpufreq_domain0 0 0>;
				};
				map4 {
					trip = <&little_alert4>;
					cooling-device = <&cpufreq_domain0 0 0>;
				};
				map5 {
					trip = <&little_alert5>;
					cooling-device = <&cpufreq_domain0 0 0>;
				};
				map6 {
					trip = <&little_alert6>;
					cooling-device = <&cpufreq_domain0 0 0>;
				};
				map7 {
					trip = <&little_hot>;
					cooling-device = <&cpufreq_domain0 0 0>;
				};
			};
		};

		gpu_thermal: G3D {
			zone_name = "G3D_THERMAL";
			polling-delay-passive = <100>;
			polling-delay = <0>;
			thermal-sensors = <&tmuctrl_2>;
			governor = "power_allocator";
			sustainable-power = <0>;
			k_po = <0>;
			k_pu = <0>;
			k_i = <0>;
			i_max = <0>;
			integral_cutoff = <0>;

			trips {
				gpu_cold: gpu-cold {
					temperature = <20000>;
					hysteresis = <5000>; /* millicelsius */
					type = "active";
				};
				gpu_switch_on: gpu-switch-on {
					temperature = <65000>; /* millicelsius */
					hysteresis = <2000>; /* millicelsius */
					type = "active";
				};
				gpu_control_temp: gpu-control-temp {
					temperature = <88000>; /* millicelsius */
					hysteresis = <5000>; /* millicelsius */
					type = "passive";
				};
				gpu_alert0: gpu-alert0 {
					temperature = <95000>; /* millicelsius */
					hysteresis = <5000>; /* millicelsius */
					type = "active";
				};
				gpu_alert1: gpu-alert1 {
					temperature = <100000>; /* millicelsius */
					hysteresis = <5000>; /* millicelsius */
					type = "active";
				};
				gpu_alert2: gpu-alert2 {
					temperature = <105000>; /* millicelsius */
					hysteresis = <5000>; /* millicelsius */
					type = "active";
				};
				gpu_alert3: gpu-alert3 {
					temperature = <110000>; /* millicelsius */
					hysteresis = <5000>; /* millicelsius */
					type = "active";
				};
				gpu_hot: gpu-hot {
					temperature = <115000>; /* millicelsius */
					hysteresis = <5000>; /* millicelsius */
					type = "hot";
				};
			};

			cooling-maps {
				map0 {
					trip = <&gpu_control_temp>;
					cooling-device = <&mali THERMAL_NO_LIMIT THERMAL_NO_LIMIT>;
				};
			};
		};

		npu_thermal: NPU {
			zone_name = "NPU_THERMAL";
			polling-delay-passive = <0>;
			polling-delay = <0>;
			thermal-sensors = <&tmuctrl_3>;
		};

		cp_thermal: CP {
			zone_name = "CP_THERMAL";
			polling-delay-passive = <0>;
			polling-delay = <0>;
			thermal-sensors = <&tmuctrl_4>;
		};
	};

};
